# CONTROLSS_G0_EPWM21_CONTROLSS_G0_EPWM21 register map
Vendor: Texas Instruments
Registers are 16-bit, read-write, reset values left out (the file's numbers can be read two ways) unless marked. A register's access mark holds for its fields unless they carry their own. Offsets are as the file gives them; [hi:lo] are bit positions.

## CONTROLSS_G0_EPWM21_CONTROLSS_G0_EPWM21 (part 2 of 4)
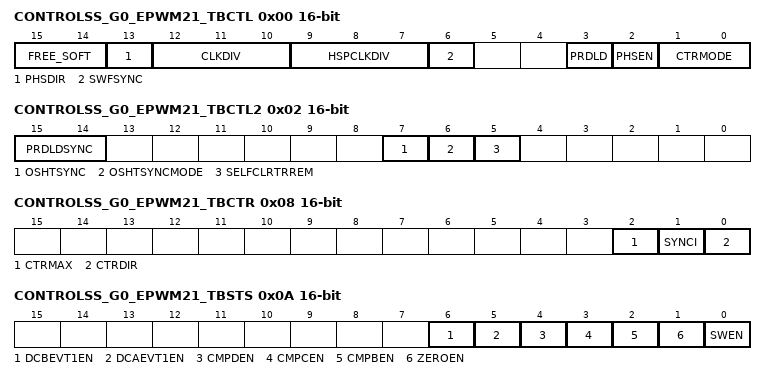
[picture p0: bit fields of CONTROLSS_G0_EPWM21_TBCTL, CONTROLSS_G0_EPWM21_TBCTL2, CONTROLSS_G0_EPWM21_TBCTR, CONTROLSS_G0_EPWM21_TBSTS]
0x00 CONTROLSS_G0_EPWM21_TBCTL access not given
  [15:14] FREE_SOFT rw — Emulation Mode Bits. These bits select the behavior of the ePWM time-base counter during emulation events 00: Stop after the next time-base counter increment or decrement 01: Stop when counter completes a whole cycle: - Up-count mode: stop when the time-base counter = period (TBCTR = TBPRD) - Down-count mode: stop when the time-base counter = 0x00 (TBCTR = 0x00) - Up-down-count mode: stop when the time-base counter = 0x00 (TBCTR = 0x00) 1x: Free run
  [13] PHSDIR rw — Phase Direction Bit This bit is only used when the time-base counter is configured in the up-down-count mode. The PHSDIR bit indicates the direction the time-base counter (TBCTR) will count after a synchronization event occurs and a new phase value is loaded from the phase (TBPHS) register. This is irrespective of the direction of the counter before the synchronization event.. In the up-count and down-count modes this bit is ignored. 0: Count down after the synchronization event. 1: Count up after the synchronization event.
  [12:10] CLKDIV rw — Time Base Clock Pre-Scale Bits These bits select the time base clock pre-scale value (TBCLK = EPWMCLK/(HSPCLKDIV * CLKDIV): 000: /1 (default on reset) 001: /2 010: /4 011: /8 100: /16 101: /32 110: /64 111: /128
  [9:7] HSPCLKDIV rw — High Speed Time Base Clock Pre-Scale Bits These bits determine part of the time-base clock prescale value. TBCLK = EPWMCLK / (HSPCLKDIV x CLKDIV). This divisor emulates the HSPCLK in the TMS320x281x system as used on the Event Manager (EV) peripheral. 000: /1 001: /2 (default on reset) 010: /4 011: /6 100: /8 101: /10 110: /12 111: /14
  [6] SWFSYNC — Software Forced Sync Pulse 0: Writing a 0 has no effect and reads always return a 0. 1: Writing a 1 forces a one-time synchronization pulse to be generated. SWFSYNC can be enabled to affect EPWMxSYNCO by setting the EPWMSYNCOUTEN.SWEN bit. (access RW RRETURNS0S)
  [3] PRDLD rw — Active Period Reg Load from Shadow Select 0: The period register (TBPRD) is loaded from its shadow register when the time-base counter, TBCTR, is equal to zero and/or a sync event as determined by the TBCTL2[PRDLDSYNC] bit. A write/read to the TBPRD register accesses the shadow register. 1: Immediate Mode (Shadow register bypassed): A write or read to the TBPRD register accesses the active register.
  [2] PHSEN rw — Counter Reg Load from Phase Reg Enable 0: Do not load the time-base counter (TBCTR) from the time-base phase register (TBPHS). 1: Allow Counter to be loaded from the Phase register (TBPHS) and shadow to active load events when an EPWMxSYNCI input signal occurs or a software-forced sync signal, see bit 6.
  [1:0] CTRMODE rw — Counter Mode The time-base counter mode is normally configured once and not changed during normal operation. If you change the mode of the counter, the change will take effect at the next TBCLK edge and the current counter value shall increment or decrement from the value before the mode change. These bits set the time-base counter mode of operation as follows: 00: Up-count mode 01: Down-count mode 10: Up-down count mode 11: Freeze counter operation (default on reset)
0x02 CONTROLSS_G0_EPWM21_TBCTL2 access not given
  [15:14] PRDLDSYNC rw — Shadow to Active Period Register Load on SYNC event 00: Shadow to Active Load of TBPRD occurs only when TBCTR = 0 (same as legacy). 01: Shadow to Active Load of TBPRD occurs both when TBCTR = 0 and when SYNC occurs. 10: Shadow to Active Load of TBPRD occurs only when a SYNC is received. 11: Reserved Note: This bit selection is valid only if TBCTL[PRDLD]=0.
  [7] OSHTSYNC — Oneshot sync bit 0: Writing a '0' has no effect. 1: Allow one sync pulse to propogate. (access RW RRETURNS0S)
  [6] OSHTSYNCMODE rw — Oneshot sync enable bit 0: Oneshot sync mode disabled 1: Oneshot sync mode enabled
  [5] SELFCLRTRREM rw — Loop back sync pulse to enable self sync operation 0: Self clear function of TRREM disabled. 1: Self clear function of TRREM enabled
0x04 CONTROLSS_G0_EPWM21_RESERVED
  [6:0] SEL — These bits determine the source of the EPWMxSYNCI signal0x0: Disabled0x01: EPWM0.SYNCOUT.0x10: EPWM15.SYNCOUT0x11:EPWM16.SYNCOUT.0x20: EPWM31.SYNCOUT0x21: Reserved.0x40: ECAP0.SYNCOUT.0x49: ECAP9.SYNCPUT0x4A: Reserved.0x4F: Reserved0x50: InputXBar.Out[4]0x51: InputXBar.Out[20]0x52: Reserved.0x57: Reserved0x58: C2K_TimeSyncXBar..SYNCPWMOut00x59: C2K_TimeSyncXBar..SYNCPWMOut10x5A: Reserved0x5F: Reserved0x60: FSIRX0.RXTRIG[0]0x61: FSIRX0.RXTRIG[1]0x62: FSIRX0.RXTRIG[2]0x63: FSIRX0.RXTRIG[3]0x64: FSIRX1.RXTRIG[0]0x65: FSIRX1.RXTRIG[1]0x66: FSIRX1.RXTRIG[2]0x67: FSIRX1.RXTRIG[3]0x68: FSIRX2.RXTRIG[0]0x69: FSIRX2.RXTRIG[1]0x6A: FSIRX2.RXTRIG[2]0x6B: FSIRX2.RXTRIG[3]0x6C: FSIRX3.RXTRIG[0]0x6D: FSIRX3.RXTRIG[1]0x6E: FSIRX3.RXTRIG[2]0x6F: FSIRX3.RXTRIG[3]0x70: Reserved.0x7F: Reserved
0x06 CONTROLSS_G0_EPWM21_EPWMSYNCINSEL
  [15:0] TBCTR — Time Base Counter Register
0x08 CONTROLSS_G0_EPWM21_TBCTR access per field
  [2] CTRMAX rw — Time-Base Counter Max Latched Status Bit 0: Reading a 0 indicates the time-base counter never reached its maximum value. Writing a 0 will have no effect. 1: Reading a 1 on this bit indicates that the time-base counter reached the max value 0xFFFF. Writing a 1 to this bit will clear the latched event.
  [1] SYNCI rw — Input Synchronization Latched Status Bit 0: Writing a 0 will have no effect. Reading a 0 indicates no external synchronization event has occurred. 1: Reading a 1 on this bit indicates that an external synchronization event has occurred (EPWMxSYNCI). Writing a 1 to this bit will clear the latched event.
  [0] CTRDIR ro — Time Base Counter Direction Status Bit 0: Time-Base Counter is currently counting down. 1: Time-Base Counter is currently counting up. Note: This bit is only valid when the counter is not frozen.
0x0A CONTROLSS_G0_EPWM21_TBSTS
  [6] DCBEVT1EN — This bit enables the DCBEVT1.sync event to set the EPWMxSYNCO signal. 0 Disabled 1 The EPWMxSYNCO signal is pulsed for one PWM clock period upon a DCBEVT1.sync event
  [5] DCAEVT1EN — This bit enables the DCAEVT1.sync event to set the EPWMxSYNCOUT signal. 0 Disabled 1 The EPWMxSYNCOUT signal is pulsed for one PWM clock period upon a DCAEVT1.sync event
  [4] CMPDEN — This bit enables the TBCTR = CMPD event to set the EPWMxSYNCO signal. 0 Disabled 1 The EPWMxSYNCO signal is pulsed for one PWM clock period upon a time-base counter equal to counter compare D event (TBCTR = CMPD)
  [3] CMPCEN — This bit enables the TBCTR = CMPC event to set the EPWMxSYNCO signal. 0 Disabled 1 The EPWMxSYNCO signal is pulsed for one PWM clock period upon a time-base counter equal to counter compare C event (TBCTR = CMPC)
  [2] CMPBEN — This bit enables the TBCTR = CMPB event to set the EPWMxSYNCO signal. 0 Disabled 1 The EPWMxSYNCO signal is pulsed for one PWM clock period upon a time-base counter equal to counter compare B event (TBCTR = CMPB)
  [1] ZEROEN — This bit enables the TBCTR = 0x0000 event to set the EPWMxSYNCOUT signal. 0 Disabled 1 The EPWMxSYNCOUT signal is pulsed for one PWM clock period upon the value of TBCTR changing to 0x0000
  [0] SWEN — This bit enables the TBCTL.SWFSYNC bit to set the EPWMxSYNCO signal. 0 Disabled 1 The EPWMxSYNCO signal is pulsed for one PWM clock period when the TBCTL.SWFSYNC bit is set
0x0C CONTROLSS_G0_EPWM21_EPWMSYNCOUTEN
  [0] OSSFRCEN — This bit determines which bit sets the EPWMxSYNCOUT One Shot Latch. 0 TBCTL2[OSHTSYNC] sets the One Shot Latch 1 GLDCTL2[OSHTLD] sets the One Shot Latch
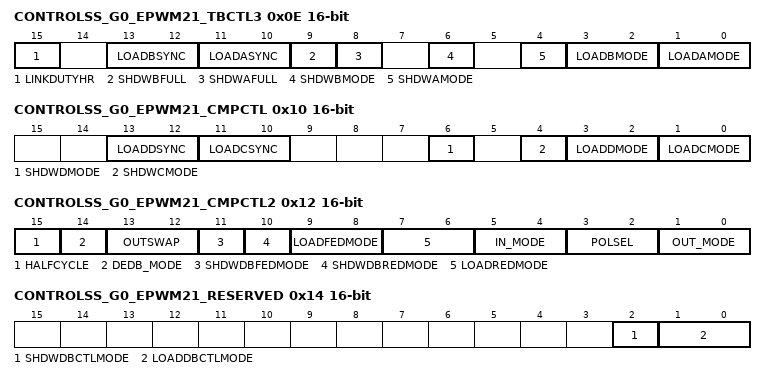
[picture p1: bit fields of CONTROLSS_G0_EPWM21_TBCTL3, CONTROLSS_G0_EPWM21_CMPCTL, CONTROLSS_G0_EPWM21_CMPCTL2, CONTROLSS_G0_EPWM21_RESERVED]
0x0E CONTROLSS_G0_EPWM21_TBCTL3 access per field
  [15] LINKDUTYHR rw — CMPAHR, CMPBHR Register Linking: 0 PWMA and PWMB outputs generated independently and CMPAHR, CMPBHR are independent values as on Type-4 1 When this bit is set CMPBHR assumes the same value as CMPAHR. This is typically used in complimentary PWM output generation (Section 7 details of the operation)
  [13:12] LOADBSYNC rw — Shadow to Active CMPB Register Load on SYNC event 00: Shadow to Active Load of CMPB:CMPBHR occurs according to LOADBMODE (bits 1,0) (same as legacy) 01: Shadow to Active Load of CMPB:CMPBHR occurs both according to LOADBMODE bits and when SYNC occurs 10: Shadow to Active Load of CMPB:CMPBHR occurs only when a SYNC is received 11: Reserved Note: This bit is valid only if CMPCTL[SHDWBMODE] = 0.
  [11:10] LOADASYNC rw — Shadow to Active CMPA Register Load on SYNC event 00: Shadow to Active Load of CMPA:CMPAHR occurs according to LOADAMODE (bits 1,0) (same as legacy) 01: Shadow to Active Load of CMPA:CMPAHR occurs both according to LOADAMODE bits and when SYNC occurs 10: Shadow to Active Load of CMPA:CMPAHR occurs only when a SYNC is received 11: Reserved Note: This bit is valid only if CMPCTL[SHDWAMODE] = 0.
  [9] SHDWBFULL ro — Counter-compare B (CMPB) Shadow Register Full Status Flag This bit self clears once a loadstrobe occurs. 0: CMPB shadow FIFO not full yet 1: Indicates the CMPB shadow FIFO is full a CPU write will overwrite current shadow value
  [8] SHDWAFULL ro — Counter-compare A (CMPA) Shadow Register Full Status Flag The flag bit is set when a 32-bit write to CMPA:CMPAHR register or a 16-bit write to CMPA register is made. A 16-bit write to CMPAHR register will not affect the flag. This bit self clears once a load-strobe occurs. 0: CMPA shadow FIFO not full yet 1: Indicates the CMPA shadow FIFO is full, a CPU write will overwrite the current shadow value
  [6] SHDWBMODE rw — Counter-compare B (CMPB) Register Operating Mode 0: Shadow mode. Operates as a double buffer. All writes via the CPU access the shadow register 1: Immediate mode. Only the active compare B register is used. All writes and reads directly access the active register for immediate compare action
  [4] SHDWAMODE rw — Counter-compare A (CMPA) Register Operating Mode 0: Shadow mode. Operates as a double buffer. All writes via the CPU access the shadow register 1: Immediate mode. Only the active compare register is used. All writes and reads directly access the active register for immediate compare action
  [3:2] LOADBMODE rw — Active Counter-Compare B (CMPB) Load From Shadow Select Mode This bit has no effect in immediate mode (CMPCTL[SHDWBMODE] = 1). 00: Load on CTR = Zero: Time-base counter equal to zero (TBCTR = 0x0000) 01: Load on CTR = PRD: Time-base counter equal to period (TBCTR = TBPRD) 10: Load on either CTR = Zero or CTR = PRD 11: Freeze (no loads possible)
  [1:0] LOADAMODE rw — Active Counter-Compare A (CMPA) Load From Shadow Select Mode This bit has no effect in immediate mode (CMPCTL[SHDWAMODE] = 1). 00: Load on CTR = Zero: Time-base counter equal to zero (TBCTR = 0x0000) 01: Load on CTR = PRD: Time-base counter equal to period (TBCTR = TBPRD) 10: Load on either CTR = Zero or CTR = PRD 11: Freeze (no loads possible)
0x10 CONTROLSS_G0_EPWM21_CMPCTL
  [13:12] LOADDSYNC — Shadow to Active CMPD Register Load on SYNC event 00: Shadow to Active Load of CMPD occurs according to LOADDMODE 01: Shadow to Active Load of CMPD occurs both according to LOADDMODE bits and when SYNC occurs 10: Shadow to Active Load of CMPD occurs only when a SYNC is received 11: Reserved Note: This bit is valid only if CMPCTL2[SHDWDMODE] = 0.
  [11:10] LOADCSYNC — Shadow to Active CMPC Register Load on SYNC event 00: Shadow to Active Load of CMPC occurs according to LOADCMODE 01: Shadow to Active Load of CMPC occurs both according to LOADCMODE bits and when SYNC occurs 10: Shadow to Active Load of CMPC occurs only when a SYNC is received 11: Reserved Note: This bit is valid only if CMPCTL2[SHDWCMODE] = 0.
  [6] SHDWDMODE — Counter-Compare D Register Operating Mode 0: Shadow mode - operates as a double buffer. All writes via the CPU access Shadow register. 1: Immediate mode - only the Active compare register is used. All writes/reads via the CPU directly access the Active register for immediate Compare action.
  [4] SHDWCMODE — Counter-Compare C Register Operating Mode 0: Shadow mode - operates as a double buffer. All writes via the CPU access Shadow register. 1: Immediate mode - only the Active compare register is used. All writes/reads via the CPU directly access the Active register for immediate Compare action.
  [3:2] LOADDMODE — Active Counter-Compare D (CMPD) Load from Shadow Select Mode 00: Load on CTR = Zero: Time-base counter equal to zero (TBCTR = 0x0000) 01: Load on CTR = PRD: Time-base counter equal to period (TBCTR = TBPRD) 10: Load on either CTR = Zero or CTR = PRD 11: Freeze (no loads possible) Note: Has no effect in Immediate mode.
  [1:0] LOADCMODE — Active Counter-Compare C (CMPC) Load from Shadow Select Mode 00: Load on CTR = Zero: Time-base counter equal to zero (TBCTR = 0x0000) 01: Load on CTR = PRD: Time-base counter equal to period (TBCTR = TBPRD) 10: Load on either CTR = Zero or CTR = PRD 11: Freeze (no loads possible) Note: Has no effect in Immediate mode.
0x12 CONTROLSS_G0_EPWM21_CMPCTL2
  [15] HALFCYCLE — Half Cycle Clocking Enable Bit 0: Full cycle clocking enabled. The dead-band counters are clocked at the TBCLK rate. 1: Half cycle clocking enabled. The dead-band counters are clocked at TBCLK*2.
  [14] DEDB_MODE — Dead Band Dual-Edge B Mode Control (S8 switch) 0: Rising edge delay applied to InA/InB as selected by S4 switch (IN-MODE bits) on A signal path only. Falling edge delay applied to InA/InB as selected by S5 switch (INMODE bits) on B signal path only. 1: Rising edge delay and falling edge delay applied to source selected by S4 switch (INMODE bits) and output to B signal path only. Note: When this bit is set to 1, user should always either set OUT_MODE bits such that Apath = InA OR OUTSWAP bits such that OutA=Bpath otherwise, OutA will be invalid.
  [13:12] OUTSWAP — Dead Band Output Swap Control Bit 13 controls the S6 switch and bit 12 controls the S7 switch. 00: OutA and OutB signals are as defined by OUT-MODE bits. 01: OutA = A-path as defined by OUT-MODE bits. OutB = A-path as defined by OUT-MODE bits (rising edge delay or delay-bypassed A signal path). 10: OutA = B-path as defined by OUT-MODE bits (falling edge delay or delay-bypassed B signal path). OutB = B-path as defined by OUT-MODE bits. 11: OutA = B-path as defined by OUT-MODE bits (falling edge delay or delay-bypassed B signal path). OutB = A-path as defined by OUT-MODE bits (rising edge delay or delay-bypassed A signal path).
  [11] SHDWDBFEDMODE — FED Dead-Band Load Mode 0: Immediate mode. Only the active DBFED register is used. All writes/reads via the CPU directly access the active register for immediate 'FED dead-band action.' 1: Shadow mode. Operates as a double buffer. All writes via the CPU access Shadow register. Default at Reset is Immediate mode (for compatibility with legacy).
  [10] SHDWDBREDMODE — RED Dead-Band Load Mode 0: Immediate mode. Only the active DBRED register is used. All writes/reads via the CPU directly access the active register for immediate 'RED dead-band action.' 1: Shadow mode. Operates as a double buffer. All writes via the CPU access Shadow register. Default at Reset is Immediate mode (for compatibility with legacy).
  [9:8] LOADFEDMODE — Active DBFED Load from Shadow Select Mode 00: Load on Counter = 0 (CNT_eq) 01: Load on Counter = Period (PRD_eq) 10: Load on either Counter = 0, or Counter = Period 11: Freeze (no loads possible) Note: has no effect in Immediate mode.
  [7:6] LOADREDMODE — Active DBRED Load from Shadow Select Mode 00: Load on Counter = 0 (CNT_eq) 01: Load on Counter = Period (PRD_eq) 10: Load on either Counter = 0, or Counter = Period 11: Freeze (no loads possible) Note: has no effect in Immediate mode.
  [5:4] IN_MODE — Dead-Band Input Mode Control Bit 5 controls the S5 switch and bit 4 controls the S4 switch shown. This allows you to select the input source to the falling-edge and rising-edge delay. To produce classical dead-band waveforms the default is EPWMxA In is the source for both falling and rising-edge delays. 00: EPWMxA In (from the action-qualifier) is the source for both falling-edge and rising-edge delay. 01: EPWMxB In (from the action-qualifier) is the source for rising-edge delayed signal. EPWMxA In (from the action-qualifier) is the source for falling-edge delayed signal. 10: EPWMxA In (from the action-qualifier) is the source for rising-edge delayed signal. EPWMxB In (from the action-qualifier) is the source for falling-edge delayed signal. 11: EPWMxB In (from the action-qualifier) is the source for both rising-edge delay and falling-edge delayed signal.
  [3:2] POLSEL — Polarity Select Control Bit 3 controls the S3 switch and bit 2 controls the S2 switch. This allows you to selectively invert one of the delayed signals before it is sent out of the dead-band submodule. The following descriptions correspond to classical upper/lower switch control as found in one leg of a digital motor control inverter. These assume that DBCTL[OUT_MODE] = 1,1 and DBCTL[IN_MODE] = 0x0. Other enhanced modes are also possible, but not regarded as typical usage modes. 00: Active high (AH) mode. Neither EPWMxA nor EPWMxB is inverted (default). 01: Active low complementary (ALC) mode. EPWMxA is inverted. 10: Active high complementary (AHC). EPWMxB is inverted. 11: Active low (AL) mode. Both EPWMxA and EPWMxB are inverted.
  [1:0] OUT_MODE — Dead-Band Output Mode Control Bit 1 controls the S1 switch and bit 0 controls the S0 switch. 00: DBM is fully disabled or by-passed. In this mode the POLSEL and IN-MODE bits have no effect. 01: Apath = InA (delay is by-passed for A signal path) Bpath = FED (Falling Edge Delay in B signal path) 10: Apath = RED (Rising Edge Delay in A signal path) Bpath = InB (delay is by-passed for B signal path) 11: DBM is fully enabled (i.e. both RED and FED active)
0x14 CONTROLSS_G0_EPWM21_RESERVED
  [2] SHDWDBCTLMODE — DBCTL Load Mode 0: Immediate mode - only the Active DBCTL register is used. All writes/reads via the CPU directly access the Active register. 1: Shadow mode - All writes and reads to bits [5:0] of the DBCTL register are shadowed. All other bits still access the active register.
  [1:0] LOADDBCTLMODE — Active DBCTL Load from Shadow Select Mode 00: Load on Counter = 0 (CNT_eq) 01: Load on Counter = Period (PRD_eq) 10: Load on either Counter = 0, or Counter = Period 11: Freeze (no loads possible) Note: has no effect in Immediate mode
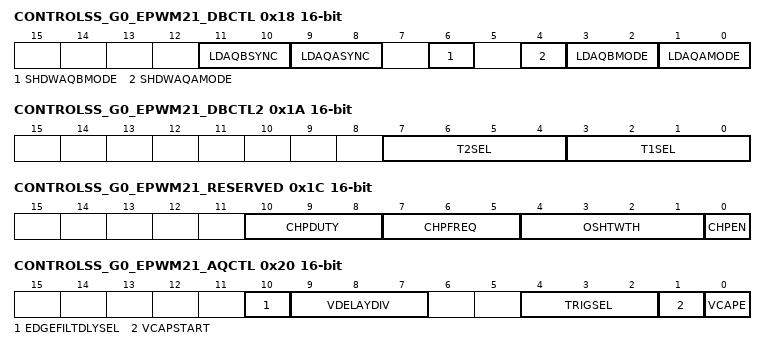
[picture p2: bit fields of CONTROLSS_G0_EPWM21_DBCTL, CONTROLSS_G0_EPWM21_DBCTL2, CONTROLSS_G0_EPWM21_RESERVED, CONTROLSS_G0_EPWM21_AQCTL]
0x18 CONTROLSS_G0_EPWM21_DBCTL
  [11:10] LDAQBSYNC — Shadow to Active AQCTLB Register Load on SYNC event 00: Shadow to Active Load of AQCTLB occurs according to LDAQBMODE 01: Shadow to Active Load of AQCTLB occurs both according to LDAQBMODE bits and when SYNC occurs. 10: Shadow to Active Load of AQCTLB occurs only when a SYNC is received. 11: Reserved Note: This bit is valid only if AQCTL[SHDWAQBMODE] = 1.
  [9:8] LDAQASYNC — Shadow to Active AQCTLA Register Load on SYNC event 00: Shadow to Active Load of AQCTLA occurs according to LDAQAMODE 01: Shadow to Active Load of AQCTLA occurs both according to LDAQAMODE bits and when SYNC occurs. 10: Shadow to Active Load of AQCTLA occurs only when a SYNC is received. 11: Reserved Note: This bit is valid only if AQCTL[SHDWAQAMODE] = 1.
  [6] SHDWAQBMODE — Action Qualifier B Register operating mode 1: Shadow mode - operates as a double buffer. All writes via the CPU access Shadow register. 0: Immediate mode - only the Active action qualifier register is used. All writes/reads via the CPU directly access the Active register.
  [4] SHDWAQAMODE — Action Qualifier A Register operating mode 1: Shadow mode - operates as a double buffer. All writes via the CPU access Shadow register. 0: Immediate mode - only the Active action qualifier register is used. All writes/reads via the CPU directly access the Active register.
  [3:2] LDAQBMODE — Active Action Qualifier B Load from Shadow Select Mode 00: Load on CTR = Zero: Time-base counter equal to zero (TBCTR = 0x0000) 01: Load on CTR = PRD: Time-base counter equal to period (TBCTR = TBPRD) 10: Load on either CTR = Zero or CTR = PRD 11: Freeze (no loads possible) Note: has no effect in Immediate mode.
  [1:0] LDAQAMODE — Active Action Qualifier A Load from Shadow Select Mode 00: Load on CTR = Zero: Time-base counter equal to zero (TBCTR = 0x0000) 01: Load on CTR = PRD: Time-base counter equal to period (TBCTR = TBPRD) 10: Load on either CTR = Zero or CTR = PRD 11: Freeze (no loads possible) Note: has no effect in Immediate mode.
0x1A CONTROLSS_G0_EPWM21_DBCTL2
  [7:4] T2SEL — T2 Event Source Select Bits 0000: DCAEVT1 0001: DCAEVT2 0010: DCBEVT1 0011: DCBEVT2 0100: TZ1 0101: TZ2 0110: TZ3 0111: EPWMxSYNCI 1000: DCEVTFILT Others: Reserved
  [3:0] T1SEL — T1 Event Source Select Bits 0000: DCAEVT1 0001: DCAEVT2 0010: DCBEVT1 0011: DCBEVT2 0100: TZ1 0101: TZ2 0110: TZ3 0111: EPWMxSYNCI 1000: DCEVTFILT Others: Reserved
0x1C CONTROLSS_G0_EPWM21_RESERVED
  [10:8] CHPDUTY — Chopping Clock Duty Cycle 000: Duty = 1/8 (12.5%) 001: Duty = 2/8 (25.0%) 010: Duty = 3/8 (37.5%) 011: Duty = 4/8 (50.0%) 100: Duty = 5/8 (62.5%) 101: Duty = 6/8 (75.0%) 110: Duty = 7/8 (87.5%) 111: Reserved
  [7:5] CHPFREQ — Chopping Clock Frequency 000: Divide by 1 (no prescale, = 12.5 MHz at 100 MHz TBCLK) 001: Divide by 2 (6.25 MHz at 100 MHz TBCLK) 010: Divide by 3 (4.16 MHz at 100 MHz TBCLK) 011: Divide by 4 (3.12 MHz at 100 MHz TBCLK) 100: Divide by 5 (2.50 MHz at 100 MHz TBCLK) 101: Divide by 6 (2.08 MHz at 100 MHz TBCLK) 110: Divide by 7 (1.78 MHz at 100 MHz TBCLK) 111: Divide by 8 (1.56 MHz at 100 MHz TBCLK)
  [4:1] OSHTWTH — One-Shot Pulse Width 0000: 1 x EPWMCLK / 8 wide ( = 80 ns at 100 MHz EPWMCLK) 0001: 2 x EPWMCLK / 8 wide ( = 160 ns at 100 MHz EPWMCLK) 0010: 3 x EPWMCLK / 8 wide ( = 240 ns at 100 MHz EPWMCLK) 0011: 4 x EPWMCLK / 8 wide ( = 320 ns at 100 MHz EPWMCLK) 0100: 5 x EPWMCLK / 8 wide ( = 400 ns at 100 MHz EPWMCLK) 0101: 6 x EPWMCLK / 8 wide ( = 480 ns at 100 MHz EPWMCLK) 0110: 7 x EPWMCLK / 8 wide ( = 560 ns at 100 MHz EPWMCLK) 0111: 8 x EPWMCLK / 8 wide ( = 640 ns at 100 MHz EPWMCLK) 1000: 9 x EPWMCLK / 8 wide ( = 720 ns at 100 MHz EPWMCLK) 1001: 10 x EPWMCLK / 8 wide ( = 800 ns at 100 MHz EPWMCLK) 1010: 11 x EPWMCLK / 8 wide ( = 880 ns at 100 MHz EPWMCLK) 1011: 12 x EPWMCLK / 8 wide ( = 960 ns at 100 MHz EPWMCLK) 1100: 13 x EPWMCLK / 8 wide ( = 1040 ns at 100 MHz EPWMCLK) 1101: 14 x EPWMCLK / 8 wide ( = 1120 ns at 100 MHz EPWMCLK) 1110: 15 x EPWMCLK / 8 wide ( = 1200 ns at 100MHz EPWMCLK) 1111: 16 x EPWMCLK / 8 wide ( = 1280 ns at 100 MHz EPWMCLK)
  [0] CHPEN — PWM-Chopping Enable 0: Disable (bypass) PWM chopping function 1: Enable chopping function
0x20 CONTROLSS_G0_EPWM21_AQCTL access not given
  [10] EDGEFILTDLYSEL rw — Valley Switching Mode Delay Selection 0: No delay applied to the edge filter output 1: HWDELAYVAL delay applied to the edge filter output
  [9:7] VDELAYDIV rw — Valley Delay Mode Divide Enable 000: HWVDELVAL = SWVDELVAL 001: HWVDELVAL = VCNTVAL+SWVDELVAL 010: HWVDELVAL = VCNTVAL''1+SWVDELVAL 011: HWVDELVAL = VCNTVAL''2+SWVDELVAL 100: HWVDELVAL = VCNTVAL''4+SWVDELVAL Note: Delay value between the consecutive edge captures can optionally be divided by using these bits.
  [4:2] TRIGSEL rw — Status of Numbered of Captured Events 000: Capture sequence is triggered by software via writes to VCAPCTL[VCAPSTART]. 001: Capture sequence is triggered by CNT_zero event. 010: Capture sequence is triggered by PRD_eq event. 011: Capture sequence is triggered by CNT_zero or PRD_eq event. 100: Capture sequence is triggered by DCAEVT1 event. 101: Capture sequence is triggered by DCAEVT2 event. 110: Capture sequence is triggered by DCBEVT1 event. 111: Capture sequence is triggered by DCBEVT2 event. Note: Valley capture sequence triggered by the selected event in this register field. Once the chosen event occurs the capture sequence is armed. Event captures occur based of the event chosen in DCFCTL[SRCSEL] register. Note: Same event may not be chosen in both DCFCTL[SRCSEL] and VCAPCTL[TRIGSEL] registers. Note: Once the chosen event in VCAPCTL[TRIGSEL] occurs, irrespective of the currentcapture status, capture sequence is retriggered.
  [1] VCAPSTART — Valley Capture Start 0: Writing a 0 has no effect 1: Trigger the capture sequence once if VCAPCTL[TRIGSEL]=0x0 Note: This bit is used to start valley capture sequence through software. VCAPCTL[TRIGSEL] has to be chosen for software trigger for this bit to have any effect. Writing of 1 will result in one capture sequence trigger. (access RW RRETURNS0S)
  [0] VCAPE rw — Valley Capture Enable/Disable 0: Disabled 1: Enabled
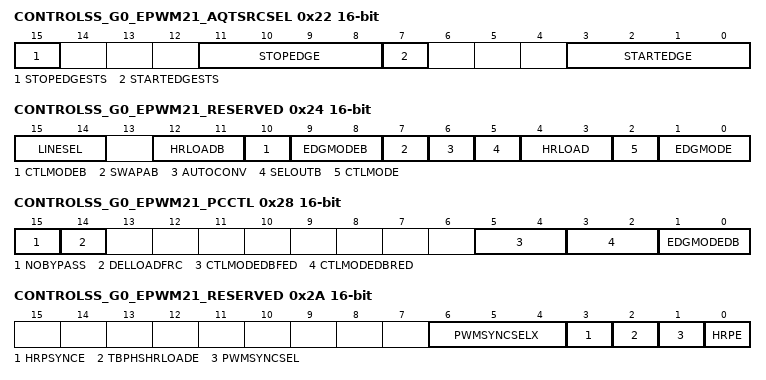
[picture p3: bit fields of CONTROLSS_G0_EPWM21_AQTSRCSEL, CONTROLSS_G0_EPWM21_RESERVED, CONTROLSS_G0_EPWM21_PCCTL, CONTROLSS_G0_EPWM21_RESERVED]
0x22 CONTROLSS_G0_EPWM21_AQTSRCSEL access per field
  [15] STOPEDGESTS ro — Stop Edge Status Bit 0: Stop edge has not occurred 1: Stop edge occurred Note: This bit is set only after the trigger sequence is armed (upon occurrence of trigger pulse selected through VCAPCTL[TRIGSEL]) and STOPEDGE occurs. Note:This bit is reset by the occurrence of the trigger pulse selected through VCAPCTL[TRIGSEL]
  [11:8] STOPEDGE rw — Counter Stop Edge Selection Once the counter operation is armed, upon occurrence of trigger pulse selected through VCAPCTL[TRIGSEL] pulse - valley counter would stop counting upon the occurrence of chosen number of events thorough this bit field. Stop counting on occurrence of: 0000: Do not stop 0001 1st edge 0010: 2nd edge 0011: 3rd edge ... 1,1,1,1: 15th edge
  [7] STARTEDGESTS ro — Start Edge Status Bit 0: Start edge has not occurred 1: Start edge occurred Note: This bit is set only after the trigger sequence is armed (upon occurrence of trigger pulse selected through VCAPCTL[TRIGSEL]) and STARTEDGE occurs. Note:This bit is reset by the occurrence of the trigger pulse selected through VCAPCTL[TRIGSEL]
  [3:0] STARTEDGE rw — Counter Start Edge Selection Once the counter operation is armed, upon occurrence of trigger pulse selected through VCAPCTL[TRIGSEL] pulse - valley counter would start counting upon the occurrence of chosen number of events thorough this bit field. Start counting on occurrence of 0000: Do not start 0001: 1st edge 0010: 2nd edge 0011: 3rd edge ... 1111: 15th edge
0x24 CONTROLSS_G0_EPWM21_RESERVED
  [15:14] LINESEL — Delay Line Selection Bits: Selects which of the 4 delay lines for a particular ePWM/EPWM module to send to CALIN for calibration.
  [12:11] HRLOADB — Shadow Mode Bit Selects the time event that loads the CMPBHR shadow value into the active register. 00: Load on CTR = Zero: Time-base counter equal to zero (TBCTR = 0x0000) 01: Load on CTR = PRD: Time-base counter equal to period (TBCTR = TBPRD) 10: Load on either CTR = Zero or CTR = PRD 11: Load on CMPB_EQ (Translator Event CMPB-3)
  [10] CTLMODEB — Control Mode Bits Selects the register (CMP/TBPRD or TBPHS) that controls the MEP: 0: CMPBHR(8) or TBPRDHR(8) Register controls the edge position (i.e., this is duty or period control mode). (Default on Reset) 1: TBPHSHR(8) Register controls the edge position (i.e., this is phase control mode).
  [9:8] EDGMODEB — Edge Mode Bits Selects the edge of the PWM that is controlled by the micro-edge position (MEP) logic: 00: HRPWM capability is disabled (default on reset) 01: MEP control of rising edge (CMPBHR) 10: MEP control of falling edge (CMPBHR) 11: MEP control of both edges (TBPHSHR or TBPRDHR)
  [7] SWAPAB — Swap ePWM A & B Output Signals This bit enables the swapping of the A & B signal outputs. The selection is as follows: 0: ePWMxA and ePWMxB outputs are unchanged. 1: ePWMxA signal appears on ePWMxB output and ePWMxB signal appears on ePWMxA output.
  [6] AUTOCONV — Auto Convert Delay Line Value Selects whether the fractional duty cycle/period/phase in the CMPAHR/TBPRDHR/TBPHSHR register is automatically scaled by the MEP scale factor in the HRMSTEP register or manually scaled by calculations in application software. The SFO library function automatically updates the HRMSTEP register with the appropriate MEP scale factor. 0: Automatic HRMSTEP scaling is disabled. 1: Automatic HRMSTEP scaling is enabled. If application software is manually scaling the fractional duty cycle, or phase (i.e. software sets CMPAHR = (fraction(PWMduty * PWMperiod) * MEP Scale Factor)<<8 + 0x080 for duty cycle), then this mode must be disabled.
  [5] SELOUTB — EPWMxB Output Select Bit This bit selects which signal is output on the ePWMxB channel output. The inversion will take the high resolution mode into account and the inverted signal will contain any high resolution modification. The inversion takes place as the last step in modifying the ePWMxB signal. 0: ePWMxB output is normal. 1: ePWMxB output is inverted version of ePWMxA signal.
  [4:3] HRLOAD — Shadow Mode Bit Selects the time event that loads the CMPAHR shadow value into the active register. 00: Load on CTR = Zero: Time-base counter equal to zero (TBCTR = 0x0000) 01: Load on CTR = PRD: Time-base counter equal to period (TBCTR = TBPRD) 10: Load on either CTR = Zero or CTR = PRD 11: Load on CMPA_EQ (Translator Event CMPA-3)
  [2] CTLMODE — Control Mode Bits Selects the register (CMP/TBPRD or TBPHS) that controls the MEP: 0: CMPAHR(8) or TBPRDHR(8) Register controls the edge position (i.e., this is duty or period control mode). (Default on Reset) 1: TBPHSHR(8) Register controls the edge position (i.e., this is phase control mode).
  [1:0] EDGMODE — Edge Mode Bits Selects the edge of the PWM that is controlled by the micro-edge position (MEP) logic: 00: HRPWM capability is disabled (default on reset) 01: MEP control of rising edge (CMPAHR) 10: MEP control of falling edge (CMPAHR) 11: MEP control of both edges (TBPHSHR or TBPRDHR)
0x28 CONTROLSS_G0_EPWM21_PCCTL access not given
  [15] NOBYPASS rw — No Bypass Delay Line Update Bit: For internal test purposes, this bit disables the 1 SYSCLK cycle bypass before delay line is updated.
  [14] DELLOADFRC — Delay Line Load Software Force: For internal test purposes, software force generates a pulse which forces a delay line update (similar to PRD_eq/CNT_zero strobe). (access RW RRETURNS0S)
  [5:4] CTLMODEDBFED rw — Shadow Mode Bit - selection should match DBCTL[LOADFEDMODE] Selects the time event that loads the DBFEDHR shadow value into the active register. 00 Load on CTR = Zero: Time-base counter equal to zero (TBCTR = 0x0000) 01 Load on CTR = PRD: Time-base counter equal to period (TBCTR = TBPRD) 10 Load on either CTR = Zero or CTR = PRD 11 Reserved
  [3:2] CTLMODEDBRED rw — Shadow Mode Bit - selection should match DBCTL[LOADREDMODE] Selects the time event that loads the DBREDHR shadow value into the active register. 00 Load on CTR = Zero: Time-base counter equal to zero (TBCTR = 0x0000) 01 Load on CTR = PRD: Time-base counter equal to period (TBCTR = TBPRD) 10 Load on either CTR = Zero or CTR = PRD 11 Reserved
  [1:0] EDGMODEDB rw — Edge Mode Bits Selects the edge of the PWM that is controlled by the micro-edge position (MEP) logic: 00 HRPWM capability is disabled (default on reset) 01 MEP control of rising edge (DBREDHR) 10 MEP control of falling edge (DBFEDHR) 11 MEP control of both edges (rising edge of DBREDHR or falling edge of DBFEDHR )
0x2A CONTROLSS_G0_EPWM21_RESERVED
  [6:4] PWMSYNCSELX — Extended selection bits for EPWMSYNCPER 000: EPWMSYNCPER is defined by PWMSYNCSEL - ' default condition (compatible with previous EPWM versions) 001: Reserved 010: Reserved 011: Reserved 100: CTR = CMPC, Count direction Up 101: CTR = CMPC, Count direction Down 110: CTR = CMPD, Count direction Up 111: CTR = CMPD, Count direction Down
  [3] HRPSYNCE — SYNC Enable Bit (TRSYNCE)/High Resolution Period SYNC Enable Bit (HRPSYNCE)
  [2] TBPHSHRLOADE — TBPHSHR Load Enable This bit allows you to synchronize ePWM modules with a high-resolution phase on a SYNCIN, TBCTL[SWFSYNC] or digital compare event. This allows for multiple ePWM modules operating at the same frequency to be phase aligned with high-resolution. 0: Disables synchronization of high-resolution phase on a SYNCIN, TBCTL[SWFSYNC] or digital compare event: 1: Synchronize the high-resolution phase on a SYNCIN, TBCTL[SWFSYNC] or digital comparator synchronization event. The phase is synchronized using the contents of the high-resolution phase TBPHSHR register. The TBCTL[PHSEN] bit which enables the loading of the TBCTR register with TBPHS register value on a SYNCIN or TBCTL[SWFSYNC] event works independently. However, users need to enable this bit also if they want to control phase in conjunction with the high-resolution period feature. This bit and the TBCTL[PHSEN] bit must be set to 1 when high-resolution period is enabled forup-down count mode even if TBPHSHR = 0x0000. This bit does not need to be set when only high-resolution duty is enabled.
  [1] PWMSYNCSEL — PWMSYNC Source Select Bit: This bit selects the source for the EPWMSYNCPER signal that goes to the CMPSS and GPDAC: 0 CTR = PRD: Time-base counter equal to period (TBCTR = TBPRD) 1 CTR = zero: Time-base counter equal to zero (TBCTR = 0x00)
  [0] HRPE — High Resolution Period Enable Bit 0: High resolution period feature disabled. In this mode the ePWM behaves as a Type 0 ePWM. 1: High resolution period enabled. In this mode the HRPWM module can control high-resolution of both the duty and frequency. When high-resolution period is enabled, TBCTL[CTRMODE] = 0,1 (down-count mode) is not supported.
0x30 CONTROLSS_G0_EPWM21_VCAPCTL
  [10:0] TRREM — HRPWM Remainder Bits: This 11-bit value keeps track of the remainder portion of the HRPWM algorithm calculations. This value keeps track of the remainder portion of the HRPWM hardware calculations. Notes: 1. The lower 8-bits of the TRREM register can be automatically initialized with the TBPHSHR value on a SYNCIN or TBCTL[SWFSYNC] event or DC event (if enabled). The user can also write a value with the CPU. 2. Priority of TRREM register updates: Sync (software or hardware) TBPHSHR copied to TRREM : Highest Priority HRPWM Hardware (updates TRREM register): Next priority CPU Write To TRREM Register: Lowest Priority 3. Bit 10 of TRREM register is not used in asymmetrical mode. This bit can be forced to zero. TRREM will be initialized to 0x0 and 0x100 in Up and Up-down modes respectively. Asymmetrical Mode: TRREM[7:0] = TBPHSHR[15:8] TRREM[10,9,8] = 0,0,0 Symmetrical Mode: TRREM[7:0] = TBPHSHR[15:8] TRREM[10,9,8] = 0,0,1
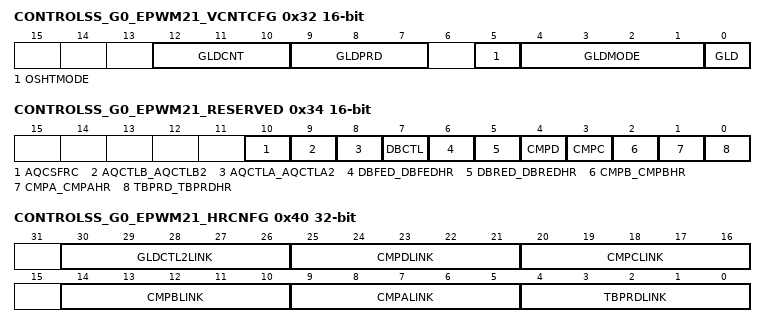
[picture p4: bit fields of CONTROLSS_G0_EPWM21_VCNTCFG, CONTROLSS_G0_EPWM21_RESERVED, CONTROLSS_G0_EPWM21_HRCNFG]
0x32 CONTROLSS_G0_EPWM21_VCNTCFG access per field
  [12:10] GLDCNT ro — Global Load Strobe Counter Register These bits indicate how many selected events have occurred: 000: No events 001: 1 event 010: 2 events 011: 3 events 100: 4 events 101: 5 events 110: 6 events 111: 7 events
  [9:7] GLDPRD rw — Global Load Strobe Period Select Register These bits select how many selected events need to occur before a load strobe is generated 000: Disable counter 001: Generate strobe on GLDCNT = 001 (1st event) 010: Generate strobe on GLDCNT = 010 (2nd event) 011: Generate strobe on GLDCNT = 011 (3rd event) 100: Generate strobe on GLDCNT = 011 (4th event) 101: Generate strobe on GLDCNT = 001 (5th event) 110: Generate strobe on GLDCNT = 010 (6th event) 111: Generate strobe on GLDCNT = 011 (7th event)
  [5] OSHTMODE rw — One Shot Load Mode Control Bit 0: One shot load mode is disabled and shadow to active loading happens continuously on all the chosen load strobes. 1: One shot mode is active. All load strobes are blocked until GLDCTL2[OSHTLD] is written with 1. Note: One Shot mode can only be used with global shadow to active load mode enabled (GLDCTL[GLD]=1)
  [4:1] GLDMODE rw — Global Load Pulse selection for Shadow to Active Mode Reloads 0000: Load on Counter = 0 (CNT_ZRO) 0001: Load on Counter = Period (PRD_EQ) 0010: Load on either Counter = 0, or Counter = Period 0011: Load on SYNCEVT - this is logical OR of DCAEVT1.sync, DCBEVT1.sync, EPWMxSYNCI and TBCTL[SWFSYNC] 0100: Load on SYNCEVT or CNT_ZRO 0101: Load on SYNCEVT or PRD_EQ 0110: Load on SYNCEVT or CNT_ZRO or PRD_EQ 1000: Load on Counter = CMPCU (CMPC_EQ counter incrementing) 1001: Load on Counter = CMPCD (CMPC_EQ counter decrementing) 1010: Load on Counter = CMPDU (CMPD_EQ counter incrementing) 1011: Load on Counter = CMPDD (CMPD_EQ counter decrementing) 1100: Reserved ... 1110: Reserved 1111: Load on GLDCTL2[GFRCLD] write
  [0] GLD rw — Global Shadow to Active Load Event Control 0: Shadow to active reload for all shadowed registers happens as per the individual reload control bits specified (Compatible with previous EPWM versions). 1: When set, all the shadow to active reload events are defined by GLDMODE bits in GLDCTL register. All the shadow registers use same reload pulse from shadow to active reloading. Individual LOADMODE bits are ignored.
0x34 CONTROLSS_G0_EPWM21_RESERVED
  [10] AQCSFRC — Global load event configuration for AQCSFRC 0: Registers use local reload configuration even if GLDCTL(GLD)=1 (reload is compatible with previous EPWMs) 1: Registers use global load configuration if this bit is set and GLDCTL(GLD)=1
  [9] AQCTLB_AQCTLB2 — Global load event configuration for AQCTLB_AQCTLB2 0: Registers use local reload configuration even if GLDCTL(GLD)=1 (reload is compatible with previous EPWMs) 1: Registers use global load configuration if this bit is set and GLDCTL(GLD)=1
  [8] AQCTLA_AQCTLA2 — Global load event configuration for AQCTLA_AQCTLA2 0: Registers use local reload configuration even if GLDCTL(GLD)=1 (reload is compatible with previous EPWMs) 1: Registers use global load configuration if this bit is set and GLDCTL(GLD)=1
  [7] DBCTL — Global load event configuration for DBCTL 0: Registers use local reload configuration even if GLDCTL(GLD)=1 (reload is compatible with previous EPWMs) 1: Registers use global load configuration if this bit is set and GLDCTL(GLD)=1
  [6] DBFED_DBFEDHR — Global load event configuration for DBFED_DBFEDHR 0: Registers use local reload configuration even if GLDCTL(GLD)=1 (reload is compatible with previous EPWMs) 1: Registers use global load configuration if this bit is set and GLDCTL(GLD)=1
  [5] DBRED_DBREDHR — Global load event configuration for DBRED_DBREDHR 0: Registers use local reload configuration even if GLDCTL(GLD)=1 (reload is compatible with previous EPWMs) 1: Registers use global load configuration if this bit is set and GLDCTL(GLD)=1
  [4] CMPD — Global load event configuration for CMPD 0: Registers use local reload configuration even if GLDCTL(GLD)=1 (reload is compatible with previous EPWMs) 1: Registers use global load configuration if this bit is set and GLDCTL(GLD)=1
  [3] CMPC — Global load event configuration for CMPC 0: Registers use local reload configuration even if GLDCTL(GLD)=1 (reload is compatible with previous EPWMs) 1: Registers use global load configuration if this bit is set and GLDCTL(GLD)=1
  [2] CMPB_CMPBHR — Global load event configuration for CMPB_CMPBHR 0: Registers use local reload configuration even if GLDCTL(GLD)=1 (reload is compatible with previous EPWMs) 1: Registers use global load configuration if this bit is set and GLDCTL(GLD)=1
  [1] CMPA_CMPAHR — Global load event configuration for CMPA_CMPAHR 0: Registers use local reload configuration even if GLDCTL(GLD)=1 (reload is compatible with previous EPWMs) 1: Registers use global load configuration if this bit is set and GLDCTL(GLD)=1
  [0] TBPRD_TBPRDHR — Global load event configuration for TBPRD_TBPRDHR 0: Registers use local reload configuration even if GLDCTL(GLD)=1 (reload is compatible with previous EPWMs) 1: Registers use global load configuration if this bit is set and GLDCTL(GLD)=1
0x40 CONTROLSS_G0_EPWM21_HRCNFG 32-bit
  [30:26] GLDCTL2LINK — GLDCTL2 Link Bits Writes to the GLDCTL2 registers in the ePWM module selected by the following bit selections results in a simultaneous write to the current ePWM module's GLDCTL2 registers. 00000: ePWM1 00001: ePWM2 00010: ePWM3 00011: ePWM4 00100: ePWM5 00101: ePWM6 00110: ePWM7 00111: ePWM8 01000: ePWM9 01001: ePWM10 01010: ePWM11 01011: ePWM12 01100: ePWM13 ... 11111: ePWM32
  [25:21] CMPDLINK — CMPD Link Bits Writes to the CMPD registers in the ePWM module selected by the following bit selections results in a simultaneous write to the current ePWM module's CMPD registers. 00000: ePWM1 00001: ePWM2 00010: ePWM3 00011: ePWM4 00100: ePWM5 00101: ePWM6 00110: ePWM7 00111: ePWM8 01000: ePWM9 01001: ePWM10 01010: ePWM11 01011: ePWM12 01100: ePWM13 ... 11111: ePWM32
  [20:16] CMPCLINK — CMPC Link Bits Writes to the CMPC registers in the ePWM module selected by the following bit selections results in a simultaneous write to the current ePWM module's CMPC registers. 00000: ePWM1 00001: ePWM2 00010: ePWM3 00011: ePWM4 00100: ePWM5 00101: ePWM6 00110: ePWM7 00111: ePWM8 01000: ePWM9 01001: ePWM10 01010: ePWM11 01011: ePWM12 01100: ePWM13 ... 11111: ePWM32
  [14:10] CMPBLINK — CMPB_CMPBHR Link Bits Writes to the CMPB_CMPBHR registers in the ePWM module selected by the following bit selections results in a simultaneous write to the current ePWM module's CMPB_CMPBHR registers. 00000: ePWM1 00001: ePWM2 00010: ePWM3 00011: ePWM4 00100: ePWM5 00101: ePWM6 00110: ePWM7 00111: ePWM8 01000: ePWM9 01001: ePWM10 01010: ePWM11 01011: ePWM12 01100: ePWM13 ... 11111: ePWM32
  [9:5] CMPALINK — CMPA_CMPAHR Link Bits Writes to the CMPA_CMPAHR registers in the ePWM module selected by the following bit selections results in a simultaneous write to the current ePWM module's CMPA_CMPAHR registers. 00000: ePWM1 00001: ePWM2 00010: ePWM3 00011: ePWM4 00100: ePWM5 00101: ePWM6 00110: ePWM7 00111: ePWM8 01000: ePWM9 01001: ePWM10 01010: ePWM11 01011: ePWM12 01100: ePWM13 ... 11111: ePWM32
  [4:0] TBPRDLINK — TBPRD_TBPRDHR Link Bits Writes to the TBPRD:TBPRDHR registers in the ePWM module selected by the following bit selections results in a simultaneous write to the current ePWM module's TBPRD_TBPRDHR registers. 00000: ePWM1 00001: ePWM2 00010: ePWM3 00011: ePWM4 00100: ePWM5 00101: ePWM6 00110: ePWM7 00111: ePWM8 01000: ePWM9 01001: ePWM10 01010: ePWM11 01011: ePWM12 01100: ePWM13 ... 11111: ePWM32
